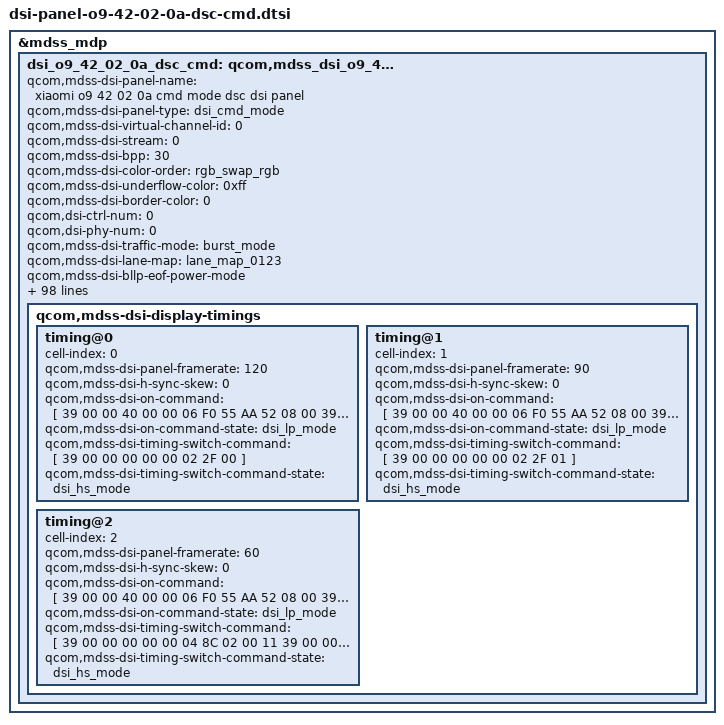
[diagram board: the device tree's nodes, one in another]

&mdss_mdp {
	dsi_o9_42_02_0a_dsc_cmd: qcom,mdss_dsi_o9_42_02_0a_dsc_cmd {
		qcom,mdss-dsi-panel-name = "xiaomi o9 42 02 0a cmd mode dsc dsi panel";
		qcom,mdss-dsi-panel-type = "dsi_cmd_mode";
		qcom,mdss-dsi-virtual-channel-id = <0>;
		qcom,mdss-dsi-stream = <0>;
		qcom,mdss-dsi-bpp = <30>;
		qcom,mdss-dsi-color-order = "rgb_swap_rgb";
		qcom,mdss-dsi-underflow-color = <0xff>;
		qcom,mdss-dsi-border-color = <0>;
		qcom,dsi-ctrl-num = <0>;
		qcom,dsi-phy-num = <0>;
		qcom,mdss-dsi-traffic-mode = "burst_mode";
		qcom,mdss-dsi-lane-map = "lane_map_0123";
		qcom,mdss-dsi-bllp-eof-power-mode;
		qcom,mdss-dsi-bllp-power-mode;
		qcom,mdss-dsi-lane-0-state;
		qcom,mdss-dsi-lane-1-state;
		qcom,mdss-dsi-lane-2-state;
		qcom,mdss-dsi-lane-3-state;
		qcom,mdss-dsi-dma-trigger = "trigger_sw";
		qcom,mdss-dsi-mdp-trigger = "none";
		qcom,mdss-dsi-reset-sequence = <1 1>, <0 2>, <1 10>;
		qcom,mdss-pan-physical-width-dimension = <682>;
		qcom,mdss-pan-physical-height-dimension = <1518>;
		qcom,mdss-dsi-te-pin-select = <1>;
		qcom,mdss-dsi-wr-mem-start = <0x2c>;
		qcom,mdss-dsi-wr-mem-continue = <0x3c>;
		qcom,mdss-dsi-te-dcs-command = <1>;
		qcom,mdss-dsi-te-check-enable;
		qcom,mdss-dsi-te-using-te-pin;
		qcom,mdss-dsi-tx-eot-append;
		qcom,mdss-dsi-lp11-init;
		qcom,mdss-dsi-bl-inverted-dbv;
		qcom,bl-update-flag = "delay_until_first_frame";
		qcom,mdss-dsi-panel-hdr-enabled;
		qcom,mdss-dsi-panel-hdr-color-primaries = <14500 15500 32000
			17000 15500 30000 8000 3000>;
		qcom,mdss-dsi-panel-peak-brightness = <17000000>;
		qcom,mdss-dsi-panel-blackness-level = <3230>;
		qcom,mdss-dsi-dma-schedule-line = <1>;
		qcom,mdss-dsi-dma-schedule-window = <50>;
		/* IRQF_ONESHOT | IRQF_TRIGGER_HIGH */
		mi,esd-err-irq-gpio = <&tlmm 175 0x2004>;
		mi,esd-err-irq-gpio-flag = <0x2004>;
		qcom,spr-pack-type = "pentile";
		mi,panel-id = <0x00004F39 0x0042020A>;
		mi,ddic-round-corner-enabled;
		qcom,mdss-disable-cesta-hw-sleep;
		mi,flat-need-sync-te;
		mi,flatmode-default-on-enabled;
		mi,flatmode-status-check-enabled;
		mi,mdss-dsi-panel-flatmode-status-command = [
			06 01 00 01 00 00 01 5F
		];
		mi,mdss-dsi-panel-flatmode-status-command-state = "dsi_hs_mode";
		mi,mdss-dsi-panel-flatmode-status-read-length = <1>;
		mi,mdss-dsi-panel-flatmode-on-status-value = <0x00>;
		mi,mdss-dsi-panel-wp-read-command = [06 01 00 01 00 00 01 A3];
		mi,mdss-dsi-panel-wp-read-command-state = "dsi_hs_mode";
		mi,mdss-dsi-panel-wp-read-pre-tx-command = [39 00 00 00 00 00 02 6F 7A];
		mi,mdss-dsi-panel-wp-read-pre-tx-command-state = "dsi_hs_mode";
		mi,mdss-dsi-panel-wp-read-length = <8>;
		mi,mdss-dsi-panel-cell-id-read-command = [06 01 00 01 00 00 01 B1];
		mi,mdss-dsi-panel-cell-id-read-pre-tx-command = [
			39 00 00 40 00 00 06 F0 55 AA 52 08 00
			15 00 00 40 00 00 02 EA 10
                        39 00 00 00 00 00 06 F0 55 AA 52 00 00
		];
		mi,mdss-dsi-panel-cell-id-read-after-tx-command = [
			39 00 00 40 00 00 06 F0 55 AA 52 08 00
			15 00 00 00 00 00 02 EA 00
		];
		mi,mdss-dsi-panel-cell-id-read-pre-tx-command-state = "dsi_hs_mode";
		mi,mdss-dsi-panel-cell-id-read-after-tx-command-state = "dsi_hs_mode";
		mi,mdss-dsi-panel-cell-id-read-command-state = "dsi_hs_mode";
		mi,mdss-dsi-panel-cell-id-read-length = <13>;
		/* esd-check reg_read */
		//qcom,esd-check-enabled;
		//qcom,esd-aod-check-enabled;
		//mi,mdss-dsi-panel-status-check-interval = <1000>;
		//qcom,mdss-dsi-panel-status-check-mode = "reg_read";
		//mi,mdss-dsi-panel-status-offset-command = [39 00 00 00 00 00 03 FF 5A 82
		//						  39 00 00 00 00 00 02 65 01];
		//qcom,mdss-dsi-panel-status-command = [06 01 00 00 00 00 01 F9];
		//mi,mdss-dsi-panel-status-after-command = [39 00 00 00 00 00 03 FF 5A 00];
		//qcom,mdss-dsi-panel-status-command-state = "dsi_lp_mode";
		//mi,mdss-dsi-panel-status-offset-command-state = "dsi_lp_mode";
		//mi,mdss-dsi-panel-status-after-command-state = "dsi_lp_mode";
		//qcom,mdss-dsi-panel-status-value = <0x08>;
		//qcom,mdss-dsi-panel-status-read-length = <1>;
		mi,panel-on-dimming-delay = <120>;
		mi,max-brightness-clone = <16383>;
		mi,mdss-dsi-fac-bl-max-level = <15603>;
		mi,mdss-fac-brightness-max-level = <15603>;
		mi,doze-hbm-dbv-level = <968>;
		mi,doze-lbm-dbv-level = <65>;
		qcom,mdss-dsi-display-timings {
			timing@0 {
				#include "dsi-panel-o9-42-02-0a-dsc-cmd-common.dtsi"
				cell-index = <0>;
				qcom,mdss-dsi-panel-framerate = <120>;
				qcom,mdss-dsi-h-sync-skew = <0>;
				qcom,mdss-dsi-on-command = [
					/* esd config */
					39 00 00 40 00 00 06 F0 55 AA 52 08 00
 					39 00 00 40 00 00 03 BE 47 45
 					39 00 00 40 00 00 02 6F 05
 					39 00 00 40 00 00 02 BE 28
 					39 00 00 40 00 00 02 6F 19
 					39 00 00 00 00 00 05 BE 10 91 00 AB
					/* init code */
					39 00 00 40 00 00 02 6F 78
					39 00 00 40 00 00 18 B0 11 00 2A 00 C2 01 DA 03 7C 05 B1 08 80 0B EE 0F FF 05 55 05 56 05 55
					39 00 00 40 00 00 02 6F 6F
					39 00 00 40 00 00 07 B0 02 6A 04 D4 02 6A
					39 00 00 40 00 00 06 F0 55 AA 52 08 08
					39 00 00 40 00 00 17 C1 8D FF DD FF FF DD FF FF DD FF FF ED FF FF EE FF FF FE FF FF 0E FF
					39 00 00 40 00 00 02 6F 20
					39 00 00 40 00 00 04 C1 4F 00 FF
					39 00 00 40 00 00 02 6F 23
					39 00 00 40 00 00 15 C1 0D FF DD FF FF DD FF FF DD FF FF ED FF FF EE FF FF AE FF A0
					39 00 00 40 00 00 05 FF AA 55 A5 82
					39 00 00 40 00 00 02 6F 09
					39 00 00 40 00 00 02 F2 FF
					39 00 00 40 00 00 06 F0 55 AA 52 08 01
					39 00 00 40 00 00 02 E5 08
					39 00 00 40 00 00 05 FF AA 55 A5 80
					39 00 00 40 00 00 02 6F 32
					39 00 00 40 00 00 02 F9 00
					39 00 00 40 00 00 05 FF AA 55 A5 81
					39 00 00 40 00 00 02 6F 02
					39 00 00 40 00 00 02 F9 84
					39 00 00 40 00 00 05 FF AA 55 A5 81
					39 00 00 40 00 00 02 6F 0C
					39 00 00 40 00 00 02 FD 08
					39 00 00 40 00 00 05 FF AA 55 A5 81
					39 00 00 40 00 00 02 6F 10
					39 00 00 40 00 00 02 FB 40
					39 00 00 40 00 00 05 FF AA 55 A5 80
					39 00 00 40 00 00 02 6F 42
					39 00 00 40 00 00 02 F4 00
					39 00 00 40 00 00 02 6F 49
					39 00 00 40 00 00 02 F2 10
					39 00 00 40 00 00 06 F0 55 AA 52 08 01
					39 00 00 40 00 00 02 6F 02
					39 00 00 40 00 00 04 C5 29 29 29
					39 00 00 40 00 00 05 FF AA 55 A5 81
					39 00 00 40 00 00 02 6F 05
					39 00 00 40 00 00 03 FE 3C 3C
					39 00 00 40 00 00 02 6F 0D
					39 00 00 40 00 00 02 FB 80
					39 00 00 40 00 00 05 FF AA 55 A5 80
					39 00 00 40 00 00 02 6F 0A
					39 00 00 40 00 00 06 F6 70 70 70 70 70
					39 00 00 40 00 00 06 F0 55 AA 52 08 00
					39 00 00 40 00 00 02 C7 44
					39 00 00 40 00 00 02 6F 31
					39 00 00 40 00 00 03 C0 01 00
					39 00 00 40 00 00 02 6F 35
					39 00 00 40 00 00 03 C0 23 20
					39 00 00 40 00 00 06 F0 55 AA 52 08 04
					39 00 00 40 00 00 02 C0 20
					39 00 00 40 00 00 06 F0 55 AA 52 08 08
					39 00 00 40 00 00 02 6F 87
					39 00 00 40 00 00 02 B8 01
					39 00 00 40 00 00 02 88 01
					39 00 00 40 00 00 02 6F 01
					39 00 00 40 00 00 05 88 02 63 09 AD
					39 00 00 40 00 00 06 F0 55 AA 52 08 01
					39 00 00 40 00 00 02 6F 05
					39 00 00 40 00 00 02 BB 01
					39 00 00 40 00 00 02 6F 0B
					39 00 00 40 00 00 02 BB A6
					39 00 00 40 00 00 02 6F 23
					39 00 00 40 00 00 02 BB 01
					39 00 00 40 00 00 02 6F 29
					39 00 00 40 00 00 02 BB A6
					39 00 00 40 00 00 02 17 30
					39 00 00 40 00 00 05 2A 00 00 04 D3
					39 00 00 40 00 00 05 2B 00 00 0A BD
					39 00 00 40 00 00 02 6F 06
					39 00 00 40 00 00 02 6D 04
					39 00 00 40 00 00 02 2F 00
					39 00 00 40 00 00 02 5F 00
					39 00 00 40 00 00 02 35 00
					39 00 00 40 00 00 03 51 00 00
					39 00 00 40 00 00 02 6F 04
					39 00 00 00 00 00 03 51 3F FF
					/* AOD */
					39 00 00 40 00 00 06 F0 55 AA 52 08 00
					39 00 00 40 00 00 02 6F 03
					39 00 00 00 00 00 02 B5 C6
					/* 0~2nit Data remapping*/
					39 00 00 40 00 00 06 F0 55 AA 52 08 00
					39 00 00 40 00 00 02 6F DF
					39 00 00 40 00 00 06 B2 00 01 00 0F 00
					39 00 00 40 00 00 02 6F 2B
					39 00 00 40 00 00 15 B2 00 00 00 00 00 00 3F FF 3F FF 3F FF 3F FF 3F FF 3F FF 3F FF
					39 00 00 40 00 00 02 6F 3F
					39 00 00 40 00 00 15 B2 3F FF 3F FF 3F FF 3F FF 3F FF 3F FF 3F FF 3F FF 3F FF 3F FF
					39 00 00 40 00 00 02 6F 53
					39 00 00 40 00 00 15 B2 3F FF 3F FF 3F FF 3F FF 3F FF 3F FF 3F FF 3F FF 3F FF 3F FF
					39 00 00 40 00 00 02 6F 67
					39 00 00 40 00 00 0B B2 3F FF 3F FF 3F FF 3F FF 3F FF
					39 00 00 40 00 00 02 6F 34
					39 00 00 40 00 00 15 B3 00 01 00 0E 00 0F 00 14 00 19 00 1D 00 23 00 28 00 2D 00 31
					39 00 00 40 00 00 02 6F 48
					39 00 00 40 00 00 15 B3 00 37 00 3C 00 41 00 46 00 53 00 64 00 78 00 8C 00 A0 00 B4
					39 00 00 40 00 00 02 6F 5C
					39 00 00 40 00 00 15 B3 00 C3 00 CE 00 FA 01 2C 01 54 01 7C 01 9B 01 9C 01 FF 03 FF
					39 00 00 40 00 00 02 6F 70
					39 00 00 40 00 00 09 B3 07 FF 0F FF 1F F5 3F FF
					39 00 00 40 00 00 02 6F 02
					39 00 00 40 00 00 02 B2 0F
					39 00 00 40 00 00 02 53 20
					39 00 00 00 00 00 02 26 00
					/* VESA */
					39 00 00 40 00 00 02 90 03
					39 00 00 40 00 00 02 6F 01
					39 00 00 40 00 00 02 90 43
					39 00 00 00 00 00 13 91 AB F0 00 32 D1 00 01 D5 01 6B 00 33 02 20 0A 11 11 50
					/* VIDEO TRIM MIPI Speed = 1100Mbps */
					39 00 00 40 00 00 06 F0 55 AA 52 08 01
					39 00 00 00 00 00 36 C3 99 29 02 67 E3 00 29 00 67 E4 00 3F 33 3D 3F 58 FB 3F 33 3D 3F 58 FB 3F 33 3D 3F 58 FB 3F 33 3D 3F 58 FB 3F 33 3D 3F 58 FB 11 11 01 00 00 00 77 00 AA 02 AA 02
					/*spr*/
					39 00 00 40 00 00 06 F0 55 AA 52 08 03
					39 00 00 40 00 00 02 6F 09
					39 00 00 40 00 00 07 DE 10 34 25 30 14 25
					39 00 00 40 00 00 06 F0 55 AA 52 08 07
					39 00 00 40 00 00 06 B0 84 44 00 00 40
					39 00 00 00 00 00 07 B1 18 08 00 08 18 00
					39 00 00 40 00 00 06 F0 55 AA 52 08 07
					39 00 00 40 00 00 06 B8 01 00 A9 0A 0F
					/* OD */
					39 00 00 40 00 00 06 F0 55 AA 52 08 08
					39 00 00 00 00 00 02 E0 01
					/*Dynamic ELVSS setting*/
					39 00 00 40 00 00 06 F0 55 AA 52 08 00
					39 00 00 40 00 00 02 6F 03
					39 00 00 00 00 00 02 B5 C6
					39 00 00 00 00 00 06 A3 81 03 D8 03 D8
					/* Display On */
					39 00 00 00 7A 00 01 11
					39 00 00 40 00 00 13 A3 81 03 D8 03 D8 02 04 B5 02 03 00 04 00 00 00 00 00 00
					39 00 00 40 00 00 02 6F 12
					39 00 00 40 00 00 0E A3 01 00 9D 00 00 AA 00 00 00 00 00 00 00
					39 00 00 40 00 00 02 6F 53
					39 00 00 40 00 00 0E A3 02 04 B5 02 03 00 08 00 00 00 00 00 00
					39 00 00 40 00 00 02 6F 60
					39 00 00 40 00 00 0E A3 01 00 9D 00 00 AA 00 00 00 00 00 00 00
					39 00 00 00 00 00 01 29
					/*Temperature compensation range:2~30nit, Smooth compensation effect*/
					39 00 00 40 00 00 06 F0 55 AA 52 08 09
					39 00 00 40 00 00 02 DD 01
					39 00 00 40 00 00 02 6F 12
					39 00 00 40 00 00 02 B2 54
					39 00 00 40 00 00 02 6F 11
					39 00 00 40 00 00 02 B2 00
					39 00 00 40 00 00 02 6F 18
					39 00 00 40 00 00 19 B2 00 00 00 00 00 00 00 00 00 00 00 00 00 00 00 00 00 00 00 00 00 00 00 00
					39 00 00 40 00 00 02 6F 12
					39 00 00 40 00 00 02 B2 54
					39 00 00 40 00 00 02 6F 11
					39 00 00 40 00 00 02 B2 01
					39 00 00 40 00 00 02 6F 18
					39 00 00 40 00 00 19 B2 00 00 00 00 00 00 00 00 00 00 00 00 00 00 00 00 00 00 00 00 00 00 00 00
					39 00 00 40 00 00 02 6F 12
					39 00 00 40 00 00 02 B2 54
					39 00 00 40 00 00 02 6F 11
					39 00 00 40 00 00 02 B2 02
					39 00 00 40 00 00 02 6F 18
					39 00 00 40 00 00 19 B2 00 00 00 00 00 00 00 00 00 00 00 00 00 00 00 00 00 00 00 00 00 00 00 00
					39 00 00 40 00 00 02 6F 12
					39 00 00 40 00 00 02 B2 55
					39 00 00 40 00 00 02 6F 11
					39 00 00 40 00 00 02 B2 00
					39 00 00 40 00 00 02 6F 18
					39 00 00 40 00 00 19 B2 00 00 00 00 00 00 00 00 00 00 00 00 00 00 00 00 00 00 00 00 00 00 00 00
					39 00 00 40 00 00 02 6F 12
					39 00 00 40 00 00 02 B2 55
					39 00 00 40 00 00 02 6F 11
					39 00 00 40 00 00 02 B2 01
					39 00 00 40 00 00 02 6F 18
					39 00 00 40 00 00 19 B2 00 00 00 00 00 00 00 00 00 00 00 00 00 00 00 00 00 00 00 00 00 00 00 00
					39 00 00 40 00 00 02 6F 12
					39 00 00 40 00 00 02 B2 55
					39 00 00 40 00 00 02 6F 11
					39 00 00 40 00 00 02 B2 02
					39 00 00 40 00 00 02 6F 18
					39 00 00 40 00 00 19 B2 00 00 00 00 00 00 00 00 00 00 00 00 00 00 00 00 00 00 00 00 00 00 00 00
					39 00 00 00 00 00 02 DD 00
					39 00 00 40 00 00 06 F0 55 AA 52 08 09
					39 00 00 40 00 00 02 DD 01
					39 00 00 40 00 00 02 6F 12
					39 00 00 40 00 00 02 B2 64
					39 00 00 40 00 00 02 6F 11
					39 00 00 40 00 00 02 B2 00
					39 00 00 40 00 00 02 6F 18
					39 00 00 40 00 00 19 B2 00 00 00 00 00 00 00 00 00 00 00 00 00 00 00 00 00 00 00 00 00 00 00 00
					39 00 00 40 00 00 02 6F 12
					39 00 00 40 00 00 02 B2 64
					39 00 00 40 00 00 02 6F 11
					39 00 00 40 00 00 02 B2 01
					39 00 00 40 00 00 02 6F 18
					39 00 00 40 00 00 19 B2 00 00 00 00 00 00 00 00 00 00 00 00 00 00 00 00 00 00 00 00 00 00 00 00
					39 00 00 40 00 00 02 6F 12
					39 00 00 40 00 00 02 B2 64
					39 00 00 40 00 00 02 6F 11
					39 00 00 40 00 00 02 B2 02
					39 00 00 40 00 00 02 6F 18
					39 00 00 40 00 00 19 B2 00 00 00 00 00 00 00 00 00 00 00 00 00 00 00 00 00 00 00 00 00 00 00 00
					39 00 00 40 00 00 02 6F 12
					39 00 00 40 00 00 02 B2 65
					39 00 00 40 00 00 02 6F 11
					39 00 00 40 00 00 02 B2 00
					39 00 00 40 00 00 02 6F 18
					39 00 00 40 00 00 19 B2 00 00 00 00 00 00 00 00 00 00 00 00 00 00 00 00 00 00 00 00 00 00 00 00
					39 00 00 40 00 00 02 6F 12
					39 00 00 40 00 00 02 B2 65
					39 00 00 40 00 00 02 6F 11
					39 00 00 40 00 00 02 B2 01
					39 00 00 40 00 00 02 6F 18
					39 00 00 40 00 00 19 B2 00 00 00 00 00 00 00 00 00 00 00 00 00 00 00 00 00 00 00 00 00 00 00 00
					39 00 00 40 00 00 02 6F 12
					39 00 00 40 00 00 02 B2 65
					39 00 00 40 00 00 02 6F 11
					39 00 00 40 00 00 02 B2 02
					39 00 00 40 00 00 02 6F 18
					39 00 00 40 00 00 19 B2 00 00 00 00 00 00 00 00 00 00 00 00 00 00 00 00 00 00 00 00 00 00 00 00
					39 00 00 00 00 00 02 DD 00
					39 00 00 40 00 00 06 F0 55 AA 52 08 09
					39 00 00 40 00 00 02 DD 01
					39 00 00 40 00 00 02 6F 12
					39 00 00 40 00 00 02 B2 74
					39 00 00 40 00 00 02 6F 11
					39 00 00 40 00 00 02 B2 00
					39 00 00 40 00 00 02 6F 18
					39 00 00 40 00 00 19 B2 00 00 00 00 00 00 00 00 00 00 00 00 00 00 00 00 00 00 00 00 00 00 00 00
					39 00 00 40 00 00 02 6F 12
					39 00 00 40 00 00 02 B2 74
					39 00 00 40 00 00 02 6F 11
					39 00 00 40 00 00 02 B2 01
					39 00 00 40 00 00 02 6F 18
					39 00 00 40 00 00 19 B2 00 00 00 00 00 00 00 00 00 00 00 00 00 00 00 00 00 00 00 00 00 00 00 00
					39 00 00 40 00 00 02 6F 12
					39 00 00 40 00 00 02 B2 74
					39 00 00 40 00 00 02 6F 11
					39 00 00 40 00 00 02 B2 02
					39 00 00 40 00 00 02 6F 18
					39 00 00 40 00 00 19 B2 00 00 00 00 00 00 00 00 00 00 00 00 00 00 00 00 00 00 00 00 00 00 00 00
					39 00 00 40 00 00 02 6F 12
					39 00 00 40 00 00 02 B2 75
					39 00 00 40 00 00 02 6F 11
					39 00 00 40 00 00 02 B2 00
					39 00 00 40 00 00 02 6F 18
					39 00 00 40 00 00 19 B2 00 00 00 00 00 00 00 00 00 00 00 00 00 00 00 00 00 00 00 00 00 00 00 00
					39 00 00 40 00 00 02 6F 12
					39 00 00 40 00 00 02 B2 75
					39 00 00 40 00 00 02 6F 11
					39 00 00 40 00 00 02 B2 01
					39 00 00 40 00 00 02 6F 18
					39 00 00 40 00 00 19 B2 00 00 00 00 00 00 00 00 00 00 00 00 00 00 00 00 00 00 00 00 00 00 00 00
					39 00 00 40 00 00 02 6F 12
					39 00 00 40 00 00 02 B2 75
					39 00 00 40 00 00 02 6F 11
					39 00 00 40 00 00 02 B2 02
					39 00 00 40 00 00 02 6F 18
					39 00 00 40 00 00 19 B2 00 00 00 00 00 00 00 00 00 00 00 00 00 00 00 00 00 00 00 00 00 00 00 00
					39 00 00 00 00 00 02 DD 00
				];
				qcom,mdss-dsi-on-command-state = "dsi_lp_mode";
				qcom,mdss-dsi-timing-switch-command = [
					/* Frame=120hz */
					39 00 00 00 00 00 02 2F 00
				];
				qcom,mdss-dsi-timing-switch-command-state = "dsi_hs_mode";
				//qcom,mdss-dsi-nolp-command = [
				//	39 00 00 00 00 00 03 51 00 00
					/* AOD OFF */
				//	05 00 00 40 00 00 01 38
				//];
				//qcom,mdss-dsi-nolp-command-update = <0x51 0 2>;
				//qcom,mdss-dsi-nolp-command-state = "dsi_hs_mode";
			};
			timing@1 {
				#include "dsi-panel-o9-42-02-0a-dsc-cmd-common.dtsi"
				cell-index = <1>;
				qcom,mdss-dsi-panel-framerate = <90>;
				qcom,mdss-dsi-h-sync-skew = <0>;
				qcom,mdss-dsi-on-command = [
					/* esd config */
					39 00 00 40 00 00 06 F0 55 AA 52 08 00
 					39 00 00 40 00 00 03 BE 47 45
 					39 00 00 40 00 00 02 6F 05
 					39 00 00 40 00 00 02 BE 28
 					39 00 00 40 00 00 02 6F 19
 					39 00 00 00 00 00 05 BE 10 91 00 AB
					/* init code */
					39 00 00 40 00 00 02 6F 78
					39 00 00 40 00 00 18 B0 11 00 2A 00 C2 01 DA 03 7C 05 B1 08 80 0B EE 0F FF 05 55 05 56 05 55
					39 00 00 40 00 00 02 6F 6F
					39 00 00 40 00 00 07 B0 02 6A 04 D4 02 6A
					39 00 00 40 00 00 06 F0 55 AA 52 08 08
					39 00 00 40 00 00 17 C1 8D FF DD FF FF DD FF FF DD FF FF ED FF FF EE FF FF FE FF FF 0E FF
					39 00 00 40 00 00 02 6F 20
					39 00 00 40 00 00 04 C1 4F 00 FF
					39 00 00 40 00 00 02 6F 23
					39 00 00 40 00 00 15 C1 0D FF DD FF FF DD FF FF DD FF FF ED FF FF EE FF FF AE FF A0
					39 00 00 40 00 00 05 FF AA 55 A5 82
					39 00 00 40 00 00 02 6F 09
					39 00 00 40 00 00 02 F2 FF
					39 00 00 40 00 00 06 F0 55 AA 52 08 01
					39 00 00 40 00 00 02 E5 08
					39 00 00 40 00 00 05 FF AA 55 A5 80
					39 00 00 40 00 00 02 6F 32
					39 00 00 40 00 00 02 F9 00
					39 00 00 40 00 00 05 FF AA 55 A5 81
					39 00 00 40 00 00 02 6F 02
					39 00 00 40 00 00 02 F9 84
					39 00 00 40 00 00 05 FF AA 55 A5 81
					39 00 00 40 00 00 02 6F 0C
					39 00 00 40 00 00 02 FD 08
					39 00 00 40 00 00 05 FF AA 55 A5 81
					39 00 00 40 00 00 02 6F 10
					39 00 00 40 00 00 02 FB 40
					39 00 00 40 00 00 05 FF AA 55 A5 80
					39 00 00 40 00 00 02 6F 42
					39 00 00 40 00 00 02 F4 00
					39 00 00 40 00 00 02 6F 49
					39 00 00 40 00 00 02 F2 10
					39 00 00 40 00 00 06 F0 55 AA 52 08 01
					39 00 00 40 00 00 02 6F 02
					39 00 00 40 00 00 04 C5 29 29 29
					39 00 00 40 00 00 05 FF AA 55 A5 81
					39 00 00 40 00 00 02 6F 05
					39 00 00 40 00 00 03 FE 3C 3C
					39 00 00 40 00 00 02 6F 0D
					39 00 00 40 00 00 02 FB 80
					39 00 00 40 00 00 05 FF AA 55 A5 80
					39 00 00 40 00 00 02 6F 0A
					39 00 00 40 00 00 06 F6 70 70 70 70 70
					39 00 00 40 00 00 06 F0 55 AA 52 08 00
					39 00 00 40 00 00 02 C7 44
					39 00 00 40 00 00 02 6F 31
					39 00 00 40 00 00 03 C0 01 00
					39 00 00 40 00 00 02 6F 35
					39 00 00 40 00 00 03 C0 23 20
					39 00 00 40 00 00 06 F0 55 AA 52 08 04
					39 00 00 40 00 00 02 C0 20
					39 00 00 40 00 00 06 F0 55 AA 52 08 08
					39 00 00 40 00 00 02 6F 87
					39 00 00 40 00 00 02 B8 01
					39 00 00 40 00 00 02 88 01
					39 00 00 40 00 00 02 6F 01
					39 00 00 40 00 00 05 88 02 63 09 AD
					39 00 00 40 00 00 06 F0 55 AA 52 08 01
					39 00 00 40 00 00 02 6F 05
					39 00 00 40 00 00 02 BB 01
					39 00 00 40 00 00 02 6F 0B
					39 00 00 40 00 00 02 BB A6
					39 00 00 40 00 00 02 6F 23
					39 00 00 40 00 00 02 BB 01
					39 00 00 40 00 00 02 6F 29
					39 00 00 40 00 00 02 BB A6
					39 00 00 40 00 00 02 17 30
					39 00 00 40 00 00 05 2A 00 00 04 D3
					39 00 00 40 00 00 05 2B 00 00 0A BD
					39 00 00 40 00 00 02 6F 06
					39 00 00 40 00 00 02 6D 04
					39 00 00 40 00 00 02 2F 01
					39 00 00 40 00 00 02 5F 00
					39 00 00 40 00 00 02 35 00
					39 00 00 40 00 00 03 51 00 00
					39 00 00 40 00 00 02 6F 04
					39 00 00 00 00 00 03 51 3F FF
					/* AOD */
					39 00 00 40 00 00 06 F0 55 AA 52 08 00
					39 00 00 40 00 00 02 6F 03
					39 00 00 00 00 00 02 B5 C6
					/* 0~2nit Data remapping*/
					39 00 00 40 00 00 06 F0 55 AA 52 08 00
					39 00 00 40 00 00 02 6F DF
					39 00 00 40 00 00 06 B2 00 01 00 0F 00
					39 00 00 40 00 00 02 6F 2B
					39 00 00 40 00 00 15 B2 00 00 00 00 00 00 3F FF 3F FF 3F FF 3F FF 3F FF 3F FF 3F FF
					39 00 00 40 00 00 02 6F 3F
					39 00 00 40 00 00 15 B2 3F FF 3F FF 3F FF 3F FF 3F FF 3F FF 3F FF 3F FF 3F FF 3F FF
					39 00 00 40 00 00 02 6F 53
					39 00 00 40 00 00 15 B2 3F FF 3F FF 3F FF 3F FF 3F FF 3F FF 3F FF 3F FF 3F FF 3F FF
					39 00 00 40 00 00 02 6F 67
					39 00 00 40 00 00 0B B2 3F FF 3F FF 3F FF 3F FF 3F FF
					39 00 00 40 00 00 02 6F 34
					39 00 00 40 00 00 15 B3 00 01 00 0E 00 0F 00 14 00 19 00 1D 00 23 00 28 00 2D 00 31
					39 00 00 40 00 00 02 6F 48
					39 00 00 40 00 00 15 B3 00 37 00 3C 00 41 00 46 00 53 00 64 00 78 00 8C 00 A0 00 B4
					39 00 00 40 00 00 02 6F 5C
					39 00 00 40 00 00 15 B3 00 C3 00 CE 00 FA 01 2C 01 54 01 7C 01 9B 01 9C 01 FF 03 FF
					39 00 00 40 00 00 02 6F 70
					39 00 00 40 00 00 09 B3 07 FF 0F FF 1F F5 3F FF
					39 00 00 40 00 00 02 6F 02
					39 00 00 40 00 00 02 B2 0F
					39 00 00 40 00 00 02 53 20
					39 00 00 00 00 00 02 26 00
					/* VESA */
					39 00 00 40 00 00 02 90 03
					39 00 00 40 00 00 02 6F 01
					39 00 00 40 00 00 02 90 43
					39 00 00 00 00 00 13 91 AB F0 00 32 D1 00 01 D5 01 6B 00 33 02 20 0A 11 11 50
					/* VIDEO TRIM MIPI Speed = 1100Mbps */
					39 00 00 40 00 00 06 F0 55 AA 52 08 01
					39 00 00 00 00 00 36 C3 99 29 02 67 E3 00 29 00 67 E4 00 3F 33 3D 3F 58 FB 3F 33 3D 3F 58 FB 3F 33 3D 3F 58 FB 3F 33 3D 3F 58 FB 3F 33 3D 3F 58 FB 11 11 01 00 00 00 77 00 AA 02 AA 02
					/*spr*/
					39 00 00 40 00 00 06 F0 55 AA 52 08 03
					39 00 00 40 00 00 02 6F 09
					39 00 00 40 00 00 07 DE 10 34 25 30 14 25
					39 00 00 40 00 00 06 F0 55 AA 52 08 07
					39 00 00 40 00 00 06 B0 84 44 00 00 40
					39 00 00 00 00 00 07 B1 18 08 00 08 18 00
					39 00 00 40 00 00 06 F0 55 AA 52 08 07
					39 00 00 40 00 00 06 B8 01 00 A9 0A 0F
					/* OD */
					39 00 00 40 00 00 06 F0 55 AA 52 08 08
					39 00 00 00 00 00 02 E0 01
					/*Dynamic ELVSS setting*/
					39 00 00 40 00 00 06 F0 55 AA 52 08 00
					39 00 00 40 00 00 02 6F 03
					39 00 00 00 00 00 02 B5 C6
					39 00 00 00 00 00 06 A3 81 03 D8 03 D8
					/* Display On */
					39 00 00 00 7A 00 01 11
					39 00 00 40 00 00 13 A3 81 03 D8 03 D8 02 04 B5 02 03 00 04 00 00 00 00 00 00
					39 00 00 40 00 00 02 6F 12
					39 00 00 40 00 00 0E A3 01 00 9D 00 00 AA 00 00 00 00 00 00 00
					39 00 00 40 00 00 02 6F 53
					39 00 00 40 00 00 0E A3 02 04 B5 02 03 00 08 00 00 00 00 00 00
					39 00 00 40 00 00 02 6F 60
					39 00 00 40 00 00 0E A3 01 00 9D 00 00 AA 00 00 00 00 00 00 00
					39 00 00 00 00 00 01 29
					/*Temperature compensation range:2~30nit, Smooth compensation effect*/
					39 00 00 40 00 00 06 F0 55 AA 52 08 09
					39 00 00 40 00 00 02 DD 01
					39 00 00 40 00 00 02 6F 12
					39 00 00 40 00 00 02 B2 54
					39 00 00 40 00 00 02 6F 11
					39 00 00 40 00 00 02 B2 00
					39 00 00 40 00 00 02 6F 18
					39 00 00 40 00 00 19 B2 00 00 00 00 00 00 00 00 00 00 00 00 00 00 00 00 00 00 00 00 00 00 00 00
					39 00 00 40 00 00 02 6F 12
					39 00 00 40 00 00 02 B2 54
					39 00 00 40 00 00 02 6F 11
					39 00 00 40 00 00 02 B2 01
					39 00 00 40 00 00 02 6F 18
					39 00 00 40 00 00 19 B2 00 00 00 00 00 00 00 00 00 00 00 00 00 00 00 00 00 00 00 00 00 00 00 00
					39 00 00 40 00 00 02 6F 12
					39 00 00 40 00 00 02 B2 54
					39 00 00 40 00 00 02 6F 11
					39 00 00 40 00 00 02 B2 02
					39 00 00 40 00 00 02 6F 18
					39 00 00 40 00 00 19 B2 00 00 00 00 00 00 00 00 00 00 00 00 00 00 00 00 00 00 00 00 00 00 00 00
					39 00 00 40 00 00 02 6F 12
					39 00 00 40 00 00 02 B2 55
					39 00 00 40 00 00 02 6F 11
					39 00 00 40 00 00 02 B2 00
					39 00 00 40 00 00 02 6F 18
					39 00 00 40 00 00 19 B2 00 00 00 00 00 00 00 00 00 00 00 00 00 00 00 00 00 00 00 00 00 00 00 00
					39 00 00 40 00 00 02 6F 12
					39 00 00 40 00 00 02 B2 55
					39 00 00 40 00 00 02 6F 11
					39 00 00 40 00 00 02 B2 01
					39 00 00 40 00 00 02 6F 18
					39 00 00 40 00 00 19 B2 00 00 00 00 00 00 00 00 00 00 00 00 00 00 00 00 00 00 00 00 00 00 00 00
					39 00 00 40 00 00 02 6F 12
					39 00 00 40 00 00 02 B2 55
					39 00 00 40 00 00 02 6F 11
					39 00 00 40 00 00 02 B2 02
					39 00 00 40 00 00 02 6F 18
					39 00 00 40 00 00 19 B2 00 00 00 00 00 00 00 00 00 00 00 00 00 00 00 00 00 00 00 00 00 00 00 00
					39 00 00 00 00 00 02 DD 00
					39 00 00 40 00 00 06 F0 55 AA 52 08 09
					39 00 00 40 00 00 02 DD 01
					39 00 00 40 00 00 02 6F 12
					39 00 00 40 00 00 02 B2 64
					39 00 00 40 00 00 02 6F 11
					39 00 00 40 00 00 02 B2 00
					39 00 00 40 00 00 02 6F 18
					39 00 00 40 00 00 19 B2 00 00 00 00 00 00 00 00 00 00 00 00 00 00 00 00 00 00 00 00 00 00 00 00
					39 00 00 40 00 00 02 6F 12
					39 00 00 40 00 00 02 B2 64
					39 00 00 40 00 00 02 6F 11
					39 00 00 40 00 00 02 B2 01
					39 00 00 40 00 00 02 6F 18
					39 00 00 40 00 00 19 B2 00 00 00 00 00 00 00 00 00 00 00 00 00 00 00 00 00 00 00 00 00 00 00 00
					39 00 00 40 00 00 02 6F 12
					39 00 00 40 00 00 02 B2 64
					39 00 00 40 00 00 02 6F 11
					39 00 00 40 00 00 02 B2 02
					39 00 00 40 00 00 02 6F 18
					39 00 00 40 00 00 19 B2 00 00 00 00 00 00 00 00 00 00 00 00 00 00 00 00 00 00 00 00 00 00 00 00
					39 00 00 40 00 00 02 6F 12
					39 00 00 40 00 00 02 B2 65
					39 00 00 40 00 00 02 6F 11
					39 00 00 40 00 00 02 B2 00
					39 00 00 40 00 00 02 6F 18
					39 00 00 40 00 00 19 B2 00 00 00 00 00 00 00 00 00 00 00 00 00 00 00 00 00 00 00 00 00 00 00 00
					39 00 00 40 00 00 02 6F 12
					39 00 00 40 00 00 02 B2 65
					39 00 00 40 00 00 02 6F 11
					39 00 00 40 00 00 02 B2 01
					39 00 00 40 00 00 02 6F 18
					39 00 00 40 00 00 19 B2 00 00 00 00 00 00 00 00 00 00 00 00 00 00 00 00 00 00 00 00 00 00 00 00
					39 00 00 40 00 00 02 6F 12
					39 00 00 40 00 00 02 B2 65
					39 00 00 40 00 00 02 6F 11
					39 00 00 40 00 00 02 B2 02
					39 00 00 40 00 00 02 6F 18
					39 00 00 40 00 00 19 B2 00 00 00 00 00 00 00 00 00 00 00 00 00 00 00 00 00 00 00 00 00 00 00 00
					39 00 00 00 00 00 02 DD 00
					39 00 00 40 00 00 06 F0 55 AA 52 08 09
					39 00 00 40 00 00 02 DD 01
					39 00 00 40 00 00 02 6F 12
					39 00 00 40 00 00 02 B2 74
					39 00 00 40 00 00 02 6F 11
					39 00 00 40 00 00 02 B2 00
					39 00 00 40 00 00 02 6F 18
					39 00 00 40 00 00 19 B2 00 00 00 00 00 00 00 00 00 00 00 00 00 00 00 00 00 00 00 00 00 00 00 00
					39 00 00 40 00 00 02 6F 12
					39 00 00 40 00 00 02 B2 74
					39 00 00 40 00 00 02 6F 11
					39 00 00 40 00 00 02 B2 01
					39 00 00 40 00 00 02 6F 18
					39 00 00 40 00 00 19 B2 00 00 00 00 00 00 00 00 00 00 00 00 00 00 00 00 00 00 00 00 00 00 00 00
					39 00 00 40 00 00 02 6F 12
					39 00 00 40 00 00 02 B2 74
					39 00 00 40 00 00 02 6F 11
					39 00 00 40 00 00 02 B2 02
					39 00 00 40 00 00 02 6F 18
					39 00 00 40 00 00 19 B2 00 00 00 00 00 00 00 00 00 00 00 00 00 00 00 00 00 00 00 00 00 00 00 00
					39 00 00 40 00 00 02 6F 12
					39 00 00 40 00 00 02 B2 75
					39 00 00 40 00 00 02 6F 11
					39 00 00 40 00 00 02 B2 00
					39 00 00 40 00 00 02 6F 18
					39 00 00 40 00 00 19 B2 00 00 00 00 00 00 00 00 00 00 00 00 00 00 00 00 00 00 00 00 00 00 00 00
					39 00 00 40 00 00 02 6F 12
					39 00 00 40 00 00 02 B2 75
					39 00 00 40 00 00 02 6F 11
					39 00 00 40 00 00 02 B2 01
					39 00 00 40 00 00 02 6F 18
					39 00 00 40 00 00 19 B2 00 00 00 00 00 00 00 00 00 00 00 00 00 00 00 00 00 00 00 00 00 00 00 00
					39 00 00 40 00 00 02 6F 12
					39 00 00 40 00 00 02 B2 75
					39 00 00 40 00 00 02 6F 11
					39 00 00 40 00 00 02 B2 02
					39 00 00 40 00 00 02 6F 18
					39 00 00 40 00 00 19 B2 00 00 00 00 00 00 00 00 00 00 00 00 00 00 00 00 00 00 00 00 00 00 00 00
					39 00 00 00 00 00 02 DD 00
				];
				qcom,mdss-dsi-on-command-state = "dsi_lp_mode";
				qcom,mdss-dsi-timing-switch-command = [
					/* Frame=90hz */
					39 00 00 00 00 00 02 2F 01
				];
				qcom,mdss-dsi-timing-switch-command-state = "dsi_hs_mode";
			};
			timing@2 {
				#include "dsi-panel-o9-42-02-0a-dsc-cmd-common.dtsi"
				cell-index = <2>;
				qcom,mdss-dsi-panel-framerate = <60>;
				qcom,mdss-dsi-h-sync-skew = <0>;
				qcom,mdss-dsi-on-command = [
					/* esd config */
					39 00 00 40 00 00 06 F0 55 AA 52 08 00
 					39 00 00 40 00 00 03 BE 47 45
 					39 00 00 40 00 00 02 6F 05
 					39 00 00 40 00 00 02 BE 28
 					39 00 00 40 00 00 02 6F 19
 					39 00 00 00 00 00 05 BE 10 91 00 AB
					/* init code */
					39 00 00 40 00 00 02 6F 78
					39 00 00 40 00 00 18 B0 11 00 2A 00 C2 01 DA 03 7C 05 B1 08 80 0B EE 0F FF 05 55 05 56 05 55
					39 00 00 40 00 00 02 6F 6F
					39 00 00 40 00 00 07 B0 02 6A 04 D4 02 6A
					39 00 00 40 00 00 06 F0 55 AA 52 08 08
					39 00 00 40 00 00 17 C1 8D FF DD FF FF DD FF FF DD FF FF ED FF FF EE FF FF FE FF FF 0E FF
					39 00 00 40 00 00 02 6F 20
					39 00 00 40 00 00 04 C1 4F 00 FF
					39 00 00 40 00 00 02 6F 23
					39 00 00 40 00 00 15 C1 0D FF DD FF FF DD FF FF DD FF FF ED FF FF EE FF FF AE FF A0
					39 00 00 40 00 00 05 FF AA 55 A5 82
					39 00 00 40 00 00 02 6F 09
					39 00 00 40 00 00 02 F2 FF
					39 00 00 40 00 00 06 F0 55 AA 52 08 01
					39 00 00 40 00 00 02 E5 08
					39 00 00 40 00 00 05 FF AA 55 A5 80
					39 00 00 40 00 00 02 6F 32
					39 00 00 40 00 00 02 F9 00
					39 00 00 40 00 00 05 FF AA 55 A5 81
					39 00 00 40 00 00 02 6F 02
					39 00 00 40 00 00 02 F9 84
					39 00 00 40 00 00 05 FF AA 55 A5 81
					39 00 00 40 00 00 02 6F 0C
					39 00 00 40 00 00 02 FD 08
					39 00 00 40 00 00 05 FF AA 55 A5 81
					39 00 00 40 00 00 02 6F 10
					39 00 00 40 00 00 02 FB 40
					39 00 00 40 00 00 05 FF AA 55 A5 80
					39 00 00 40 00 00 02 6F 42
					39 00 00 40 00 00 02 F4 00
					39 00 00 40 00 00 02 6F 49
					39 00 00 40 00 00 02 F2 10
					39 00 00 40 00 00 06 F0 55 AA 52 08 01
					39 00 00 40 00 00 02 6F 02
					39 00 00 40 00 00 04 C5 29 29 29
					39 00 00 40 00 00 05 FF AA 55 A5 81
					39 00 00 40 00 00 02 6F 05
					39 00 00 40 00 00 03 FE 3C 3C
					39 00 00 40 00 00 02 6F 0D
					39 00 00 40 00 00 02 FB 80
					39 00 00 40 00 00 05 FF AA 55 A5 80
					39 00 00 40 00 00 02 6F 0A
					39 00 00 40 00 00 06 F6 70 70 70 70 70
					39 00 00 40 00 00 06 F0 55 AA 52 08 00
					39 00 00 40 00 00 02 C7 44
					39 00 00 40 00 00 02 6F 31
					39 00 00 40 00 00 03 C0 01 00
					39 00 00 40 00 00 02 6F 35
					39 00 00 40 00 00 03 C0 23 20
					39 00 00 40 00 00 06 F0 55 AA 52 08 04
					39 00 00 40 00 00 02 C0 20
					39 00 00 40 00 00 06 F0 55 AA 52 08 08
					39 00 00 40 00 00 02 6F 87
					39 00 00 40 00 00 02 B8 01
					39 00 00 40 00 00 02 88 01
					39 00 00 40 00 00 02 6F 01
					39 00 00 40 00 00 05 88 02 63 09 AD
					39 00 00 40 00 00 06 F0 55 AA 52 08 01
					39 00 00 40 00 00 02 6F 05
					39 00 00 40 00 00 02 BB 01
					39 00 00 40 00 00 02 6F 0B
					39 00 00 40 00 00 02 BB A6
					39 00 00 40 00 00 02 6F 23
					39 00 00 40 00 00 02 BB 01
					39 00 00 40 00 00 02 6F 29
					39 00 00 40 00 00 02 BB A6
					39 00 00 40 00 00 02 17 30
					39 00 00 40 00 00 05 2A 00 00 04 D3
					39 00 00 40 00 00 05 2B 00 00 0A BD
					39 00 00 40 00 00 02 6F 06
					39 00 00 40 00 00 02 6D 04
					39 00 00 40 00 00 02 5A 01
					39 00 00 40 00 00 02 2F 30
					39 00 00 40 00 00 02 6D 00
					39 00 00 40 00 00 02 5F 00
					39 00 00 40 00 00 02 35 00
					39 00 00 40 00 00 03 51 00 00
					39 00 00 40 00 00 02 6F 04
					39 00 00 00 00 00 03 51 3F FF
					/* AOD */
					39 00 00 40 00 00 06 F0 55 AA 52 08 00
					39 00 00 40 00 00 02 6F 03
					39 00 00 00 00 00 02 B5 C6
					/* 0~2nit Data remapping*/
					39 00 00 40 00 00 06 F0 55 AA 52 08 00
					39 00 00 40 00 00 02 6F DF
					39 00 00 40 00 00 06 B2 00 01 00 0F 00
					39 00 00 40 00 00 02 6F 2B
					39 00 00 40 00 00 15 B2 00 00 00 00 00 00 3F FF 3F FF 3F FF 3F FF 3F FF 3F FF 3F FF
					39 00 00 40 00 00 02 6F 3F
					39 00 00 40 00 00 15 B2 3F FF 3F FF 3F FF 3F FF 3F FF 3F FF 3F FF 3F FF 3F FF 3F FF
					39 00 00 40 00 00 02 6F 53
					39 00 00 40 00 00 15 B2 3F FF 3F FF 3F FF 3F FF 3F FF 3F FF 3F FF 3F FF 3F FF 3F FF
					39 00 00 40 00 00 02 6F 67
					39 00 00 40 00 00 0B B2 3F FF 3F FF 3F FF 3F FF 3F FF
					39 00 00 40 00 00 02 6F 34
					39 00 00 40 00 00 15 B3 00 01 00 0E 00 0F 00 14 00 19 00 1D 00 23 00 28 00 2D 00 31
					39 00 00 40 00 00 02 6F 48
					39 00 00 40 00 00 15 B3 00 37 00 3C 00 41 00 46 00 53 00 64 00 78 00 8C 00 A0 00 B4
					39 00 00 40 00 00 02 6F 5C
					39 00 00 40 00 00 15 B3 00 C3 00 CE 00 FA 01 2C 01 54 01 7C 01 9B 01 9C 01 FF 03 FF
					39 00 00 40 00 00 02 6F 70
					39 00 00 40 00 00 09 B3 07 FF 0F FF 1F F5 3F FF
					39 00 00 40 00 00 02 6F 02
					39 00 00 40 00 00 02 B2 0F
					39 00 00 40 00 00 02 53 20
					39 00 00 00 00 00 02 26 00
					/*backlight off the back fun*/
					39 00 00 00 00 00 04 8C 02 00 11
					/* VESA */
					39 00 00 40 00 00 02 90 03
					39 00 00 40 00 00 02 6F 01
					39 00 00 40 00 00 02 90 43
					39 00 00 00 00 00 13 91 AB F0 00 32 D1 00 01 D5 01 6B 00 33 02 20 0A 11 11 50
					/* VIDEO TRIM MIPI Speed = 1100Mbps */
					39 00 00 40 00 00 06 F0 55 AA 52 08 01
					39 00 00 00 00 00 36 C3 99 29 02 67 E3 00 29 00 67 E4 00 3F 33 3D 3F 58 FB 3F 33 3D 3F 58 FB 3F 33 3D 3F 58 FB 3F 33 3D 3F 58 FB 3F 33 3D 3F 58 FB 11 11 01 00 00 00 77 00 AA 02 AA 02
					/*spr*/
					39 00 00 40 00 00 06 F0 55 AA 52 08 03
					39 00 00 40 00 00 02 6F 09
					39 00 00 40 00 00 07 DE 10 34 25 30 14 25
					39 00 00 40 00 00 06 F0 55 AA 52 08 07
					39 00 00 40 00 00 06 B0 84 44 00 00 40
					39 00 00 00 00 00 07 B1 18 08 00 08 18 00
					39 00 00 40 00 00 06 F0 55 AA 52 08 07
					39 00 00 40 00 00 06 B8 01 00 A9 0A 0F
					/* OD */
					39 00 00 40 00 00 06 F0 55 AA 52 08 08
					39 00 00 00 00 00 02 E0 01
					/*Dynamic ELVSS setting*/
					39 00 00 40 00 00 06 F0 55 AA 52 08 00
					39 00 00 40 00 00 02 6F 03
					39 00 00 00 00 00 02 B5 C6
					39 00 00 00 00 00 06 A3 81 03 D8 03 D8
					/* Display On */
					39 00 00 00 7A 00 01 11
					39 00 00 40 00 00 13 A3 81 03 D8 03 D8 02 04 B5 02 03 00 04 00 00 00 00 00 00
					39 00 00 40 00 00 02 6F 12
					39 00 00 40 00 00 0E A3 01 00 9D 00 00 AA 00 00 00 00 00 00 00
					39 00 00 40 00 00 02 6F 53
					39 00 00 40 00 00 0E A3 02 04 B5 02 03 00 08 00 00 00 00 00 00
					39 00 00 40 00 00 02 6F 60
					39 00 00 40 00 00 0E A3 01 00 9D 00 00 AA 00 00 00 00 00 00 00
					39 00 00 00 00 00 01 29
					/*Temperature compensation range:2~30nit, Smooth compensation effect*/
					39 00 00 40 00 00 06 F0 55 AA 52 08 09
					39 00 00 40 00 00 02 DD 01
					39 00 00 40 00 00 02 6F 12
					39 00 00 40 00 00 02 B2 54
					39 00 00 40 00 00 02 6F 11
					39 00 00 40 00 00 02 B2 00
					39 00 00 40 00 00 02 6F 18
					39 00 00 40 00 00 19 B2 00 00 00 00 00 00 00 00 00 00 00 00 00 00 00 00 00 00 00 00 00 00 00 00
					39 00 00 40 00 00 02 6F 12
					39 00 00 40 00 00 02 B2 54
					39 00 00 40 00 00 02 6F 11
					39 00 00 40 00 00 02 B2 01
					39 00 00 40 00 00 02 6F 18
					39 00 00 40 00 00 19 B2 00 00 00 00 00 00 00 00 00 00 00 00 00 00 00 00 00 00 00 00 00 00 00 00
					39 00 00 40 00 00 02 6F 12
					39 00 00 40 00 00 02 B2 54
					39 00 00 40 00 00 02 6F 11
					39 00 00 40 00 00 02 B2 02
					39 00 00 40 00 00 02 6F 18
					39 00 00 40 00 00 19 B2 00 00 00 00 00 00 00 00 00 00 00 00 00 00 00 00 00 00 00 00 00 00 00 00
					39 00 00 40 00 00 02 6F 12
					39 00 00 40 00 00 02 B2 55
					39 00 00 40 00 00 02 6F 11
					39 00 00 40 00 00 02 B2 00
					39 00 00 40 00 00 02 6F 18
					39 00 00 40 00 00 19 B2 00 00 00 00 00 00 00 00 00 00 00 00 00 00 00 00 00 00 00 00 00 00 00 00
					39 00 00 40 00 00 02 6F 12
					39 00 00 40 00 00 02 B2 55
					39 00 00 40 00 00 02 6F 11
					39 00 00 40 00 00 02 B2 01
					39 00 00 40 00 00 02 6F 18
					39 00 00 40 00 00 19 B2 00 00 00 00 00 00 00 00 00 00 00 00 00 00 00 00 00 00 00 00 00 00 00 00
					39 00 00 40 00 00 02 6F 12
					39 00 00 40 00 00 02 B2 55
					39 00 00 40 00 00 02 6F 11
					39 00 00 40 00 00 02 B2 02
					39 00 00 40 00 00 02 6F 18
					39 00 00 40 00 00 19 B2 00 00 00 00 00 00 00 00 00 00 00 00 00 00 00 00 00 00 00 00 00 00 00 00
					39 00 00 00 00 00 02 DD 00
					39 00 00 40 00 00 06 F0 55 AA 52 08 09
					39 00 00 40 00 00 02 DD 01
					39 00 00 40 00 00 02 6F 12
					39 00 00 40 00 00 02 B2 64
					39 00 00 40 00 00 02 6F 11
					39 00 00 40 00 00 02 B2 00
					39 00 00 40 00 00 02 6F 18
					39 00 00 40 00 00 19 B2 00 00 00 00 00 00 00 00 00 00 00 00 00 00 00 00 00 00 00 00 00 00 00 00
					39 00 00 40 00 00 02 6F 12
					39 00 00 40 00 00 02 B2 64
					39 00 00 40 00 00 02 6F 11
					39 00 00 40 00 00 02 B2 01
					39 00 00 40 00 00 02 6F 18
					39 00 00 40 00 00 19 B2 00 00 00 00 00 00 00 00 00 00 00 00 00 00 00 00 00 00 00 00 00 00 00 00
					39 00 00 40 00 00 02 6F 12
					39 00 00 40 00 00 02 B2 64
					39 00 00 40 00 00 02 6F 11
					39 00 00 40 00 00 02 B2 02
					39 00 00 40 00 00 02 6F 18
					39 00 00 40 00 00 19 B2 00 00 00 00 00 00 00 00 00 00 00 00 00 00 00 00 00 00 00 00 00 00 00 00
					39 00 00 40 00 00 02 6F 12
					39 00 00 40 00 00 02 B2 65
					39 00 00 40 00 00 02 6F 11
					39 00 00 40 00 00 02 B2 00
					39 00 00 40 00 00 02 6F 18
					39 00 00 40 00 00 19 B2 00 00 00 00 00 00 00 00 00 00 00 00 00 00 00 00 00 00 00 00 00 00 00 00
					39 00 00 40 00 00 02 6F 12
					39 00 00 40 00 00 02 B2 65
					39 00 00 40 00 00 02 6F 11
					39 00 00 40 00 00 02 B2 01
					39 00 00 40 00 00 02 6F 18
					39 00 00 40 00 00 19 B2 00 00 00 00 00 00 00 00 00 00 00 00 00 00 00 00 00 00 00 00 00 00 00 00
					39 00 00 40 00 00 02 6F 12
					39 00 00 40 00 00 02 B2 65
					39 00 00 40 00 00 02 6F 11
					39 00 00 40 00 00 02 B2 02
					39 00 00 40 00 00 02 6F 18
					39 00 00 40 00 00 19 B2 00 00 00 00 00 00 00 00 00 00 00 00 00 00 00 00 00 00 00 00 00 00 00 00
					39 00 00 00 00 00 02 DD 00
					39 00 00 40 00 00 06 F0 55 AA 52 08 09
					39 00 00 40 00 00 02 DD 01
					39 00 00 40 00 00 02 6F 12
					39 00 00 40 00 00 02 B2 74
					39 00 00 40 00 00 02 6F 11
					39 00 00 40 00 00 02 B2 00
					39 00 00 40 00 00 02 6F 18
					39 00 00 40 00 00 19 B2 00 00 00 00 00 00 00 00 00 00 00 00 00 00 00 00 00 00 00 00 00 00 00 00
					39 00 00 40 00 00 02 6F 12
					39 00 00 40 00 00 02 B2 74
					39 00 00 40 00 00 02 6F 11
					39 00 00 40 00 00 02 B2 01
					39 00 00 40 00 00 02 6F 18
					39 00 00 40 00 00 19 B2 00 00 00 00 00 00 00 00 00 00 00 00 00 00 00 00 00 00 00 00 00 00 00 00
					39 00 00 40 00 00 02 6F 12
					39 00 00 40 00 00 02 B2 74
					39 00 00 40 00 00 02 6F 11
					39 00 00 40 00 00 02 B2 02
					39 00 00 40 00 00 02 6F 18
					39 00 00 40 00 00 19 B2 00 00 00 00 00 00 00 00 00 00 00 00 00 00 00 00 00 00 00 00 00 00 00 00
					39 00 00 40 00 00 02 6F 12
					39 00 00 40 00 00 02 B2 75
					39 00 00 40 00 00 02 6F 11
					39 00 00 40 00 00 02 B2 00
					39 00 00 40 00 00 02 6F 18
					39 00 00 40 00 00 19 B2 00 00 00 00 00 00 00 00 00 00 00 00 00 00 00 00 00 00 00 00 00 00 00 00
					39 00 00 40 00 00 02 6F 12
					39 00 00 40 00 00 02 B2 75
					39 00 00 40 00 00 02 6F 11
					39 00 00 40 00 00 02 B2 01
					39 00 00 40 00 00 02 6F 18
					39 00 00 40 00 00 19 B2 00 00 00 00 00 00 00 00 00 00 00 00 00 00 00 00 00 00 00 00 00 00 00 00
					39 00 00 40 00 00 02 6F 12
					39 00 00 40 00 00 02 B2 75
					39 00 00 40 00 00 02 6F 11
					39 00 00 40 00 00 02 B2 02
					39 00 00 40 00 00 02 6F 18
					39 00 00 40 00 00 19 B2 00 00 00 00 00 00 00 00 00 00 00 00 00 00 00 00 00 00 00 00 00 00 00 00
					39 00 00 00 00 00 02 DD 00
				];
				qcom,mdss-dsi-on-command-state = "dsi_lp_mode";
				qcom,mdss-dsi-timing-switch-command = [
					/*backlight off the back fun*/
					39 00 00 00 00 00 04 8C 02 00 11
					/* Frame=60hz */
					39 00 00 40 00 00 02 5A 01
					39 00 00 40 00 00 02 2F 30
					39 00 00 00 00 00 02 6D 00
				];
				qcom,mdss-dsi-timing-switch-command-state = "dsi_hs_mode";
			};
		};
	};
};
&dsi_o9_42_02_0a_dsc_cmd {
	qcom,panel-supply-entries = <&dsi_panel_pwr_supply_O9>;
	qcom,mdss-dsi-bl-pmic-control-type = "bl_ctrl_dcs";
	qcom,mdss-dsi-bl-min-level = <15>;
	qcom,mdss-dsi-bl-max-level = <16383>;
	qcom,bl-dsc-cmd-state = "dsi_hs_mode";
	qcom,mdss-brightness-max-level = <16383>;
	qcom,mdss-brightness-init-level = <1228>;
	qcom,platform-reset-gpio = <&tlmm 14 0>;
	mi,panel-build-id-read-needed;
	mi,panel-build-id-read-length = <1>;
	mi,mdss-dsi-panel-build-id-read-command = [06 01 00 01 00 00 01 DA];
	mi,mdss-dsi-panel-build-id-read-command-state = "dsi_hs_mode";
	mi,disable-ic-dimming-flag;
	qcom,mdss-dsi-panel-vsync-delay;
	qcom,ulps-enabled;
	qcom,dsi-select-clocks = "pll_byte_clk0", "pll_dsi_clk0";
	qcom,mdss-dsi-clk-strength = <0xFF>;
	mi,local-hbm-enabled;
	mi,need-fod-animal-in-normal-enabled;
	mi,local-hbm-ui-ready-delay-num-frame = <5>; /* 5 frame */
	//qcom,mdss-dsi-deemph-eq-strength = <0x88>;
	mi,panel-forbid-fps-switch-in-aod;
};
